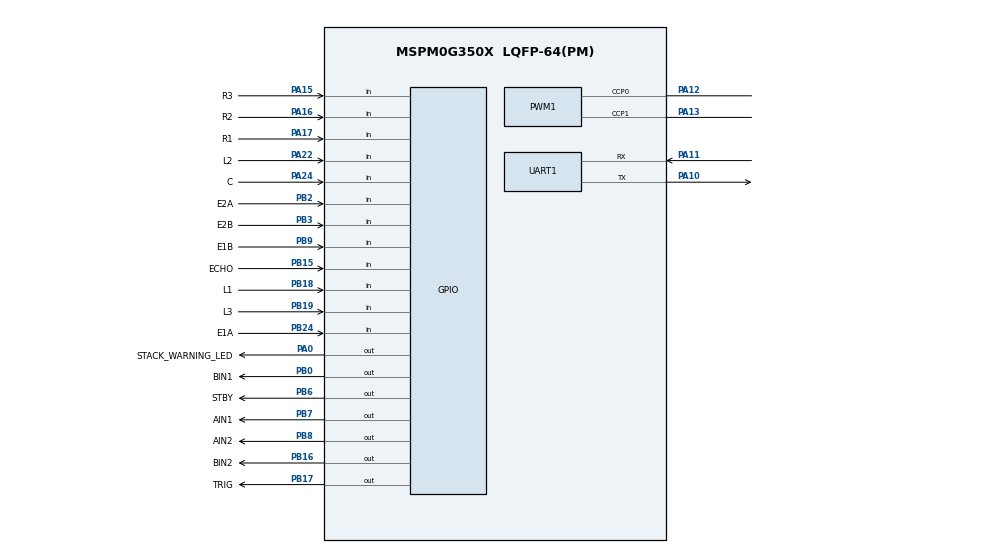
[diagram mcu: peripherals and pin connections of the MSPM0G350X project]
/**
 * @cliArgs --device "MSPM0G350X" --part "Default" --package "LQFP-64(PM)" --product "mspm0_sdk@2.10.00.04"
 * @versions {"tool":"1.27.0+4565"}
 */

/**
 * Import the modules used in this configuration.
 */
const Board         = scripting.addModule("/ti/driverlib/Board");
const GPIO          = scripting.addModule("/ti/driverlib/GPIO", {}, false);
const GPIO1         = GPIO.addInstance();
const GPIO2         = GPIO.addInstance();
const GPIO3         = GPIO.addInstance();
const GPIO4         = GPIO.addInstance();
const PWM           = scripting.addModule("/ti/driverlib/PWM", {}, false);
const PWM1          = PWM.addInstance();
const SYSCTL        = scripting.addModule("/ti/driverlib/SYSCTL");
const TIMER         = scripting.addModule("/ti/driverlib/TIMER", {}, false);
const TIMER1        = TIMER.addInstance();
const UART          = scripting.addModule("/ti/driverlib/UART", {}, false);
const UART1         = UART.addInstance();
const ProjectConfig = scripting.addModule("/ti/project_config/ProjectConfig");

/**
 * Write custom configuration values to the imported modules.
 */
const divider9       = system.clockTree["UDIV"];
divider9.divideValue = 2;

const multiplier2         = system.clockTree["PLL_QDIV"];
multiplier2.multiplyValue = 5;

const mux8       = system.clockTree["HSCLKMUX"];
mux8.inputSelect = "HSCLKMUX_SYSPLL0";

Board.configureUnused = true;
Board.unusedDirection = "INPUT";

GPIO1.$name                          = "GPIO_LEDS";
GPIO1.associatedPins[0].assignedPin  = "0";
GPIO1.associatedPins[0].$name        = "STACK_WARNING_LED";
GPIO1.associatedPins[0].assignedPort = "PORTA";
GPIO1.associatedPins[0].initialValue = "SET";
GPIO1.associatedPins[0].pin.$assign  = "PA0";

GPIO2.$name                          = "GPIO_TRACE";
GPIO2.associatedPins.create(7);
GPIO2.associatedPins[0].direction    = "INPUT";
GPIO2.associatedPins[0].assignedPort = "PORTB";
GPIO2.associatedPins[0].assignedPin  = "19";
GPIO2.associatedPins[0].$name        = "L3";
GPIO2.associatedPins[0].pin.$assign  = "PB19";
GPIO2.associatedPins[1].direction    = "INPUT";
GPIO2.associatedPins[1].assignedPin  = "22";
GPIO2.associatedPins[1].assignedPort = "PORTA";
GPIO2.associatedPins[1].$name        = "L2";
GPIO2.associatedPins[1].pin.$assign  = "PA22";
GPIO2.associatedPins[2].direction    = "INPUT";
GPIO2.associatedPins[2].assignedPort = "PORTB";
GPIO2.associatedPins[2].assignedPin  = "18";
GPIO2.associatedPins[2].$name        = "L1";
GPIO2.associatedPins[2].pin.$assign  = "PB18";
GPIO2.associatedPins[3].direction    = "INPUT";
GPIO2.associatedPins[3].assignedPort = "PORTA";
GPIO2.associatedPins[3].$name        = "C";
GPIO2.associatedPins[3].assignedPin  = "24";
GPIO2.associatedPins[3].pin.$assign  = "PA24";
GPIO2.associatedPins[4].direction    = "INPUT";
GPIO2.associatedPins[4].assignedPort = "PORTA";
GPIO2.associatedPins[4].$name        = "R1";
GPIO2.associatedPins[4].assignedPin  = "17";
GPIO2.associatedPins[4].pin.$assign  = "PA17";
GPIO2.associatedPins[5].direction    = "INPUT";
GPIO2.associatedPins[5].assignedPort = "PORTA";
GPIO2.associatedPins[5].$name        = "R2";
GPIO2.associatedPins[5].assignedPin  = "16";
GPIO2.associatedPins[5].pin.$assign  = "PA16";
GPIO2.associatedPins[6].direction    = "INPUT";
GPIO2.associatedPins[6].assignedPort = "PORTA";
GPIO2.associatedPins[6].$name        = "R3";
GPIO2.associatedPins[6].assignedPin  = "15";
GPIO2.associatedPins[6].pin.$assign  = "PA15";

GPIO3.$name                               = "GPIO_MOTOR";
GPIO3.port                                = "PORTB";
GPIO3.associatedPins.create(9);
GPIO3.associatedPins[0].$name             = "STBY";
GPIO3.associatedPins[0].assignedPin       = "6";
GPIO3.associatedPins[0].pin.$assign       = "PB6";
GPIO3.associatedPins[1].$name             = "AIN1";
GPIO3.associatedPins[1].assignedPin       = "7";
GPIO3.associatedPins[1].pin.$assign       = "PB7";
GPIO3.associatedPins[2].$name             = "AIN2";
GPIO3.associatedPins[2].assignedPin       = "8";
GPIO3.associatedPins[2].pin.$assign       = "PB8";
GPIO3.associatedPins[3].$name             = "BIN1";
GPIO3.associatedPins[3].assignedPin       = "0";
GPIO3.associatedPins[3].pin.$assign       = "PB0";
GPIO3.associatedPins[4].$name             = "BIN2";
GPIO3.associatedPins[4].assignedPin       = "16";
GPIO3.associatedPins[4].pin.$assign       = "PB16";
GPIO3.associatedPins[5].$name             = "E1A";
GPIO3.associatedPins[5].direction         = "INPUT";
GPIO3.associatedPins[5].interruptEn       = true;
GPIO3.associatedPins[5].interruptPriority = "2";
GPIO3.associatedPins[5].polarity          = "RISE_FALL";
GPIO3.associatedPins[5].assignedPin       = "24";
GPIO3.associatedPins[5].pin.$assign       = "PB24";
GPIO3.associatedPins[6].$name             = "E1B";
GPIO3.associatedPins[6].direction         = "INPUT";
GPIO3.associatedPins[6].interruptEn       = true;
GPIO3.associatedPins[6].interruptPriority = "2";
GPIO3.associatedPins[6].polarity          = "RISE_FALL";
GPIO3.associatedPins[6].assignedPin       = "9";
GPIO3.associatedPins[6].pin.$assign       = "PB9";
GPIO3.associatedPins[7].$name             = "E2A";
GPIO3.associatedPins[7].direction         = "INPUT";
GPIO3.associatedPins[7].polarity          = "RISE_FALL";
GPIO3.associatedPins[7].interruptEn       = true;
GPIO3.associatedPins[7].interruptPriority = "2";
GPIO3.associatedPins[7].assignedPin       = "2";
GPIO3.associatedPins[7].pin.$assign       = "PB2";
GPIO3.associatedPins[8].$name             = "E2B";
GPIO3.associatedPins[8].direction         = "INPUT";
GPIO3.associatedPins[8].interruptEn       = true;
GPIO3.associatedPins[8].interruptPriority = "2";
GPIO3.associatedPins[8].polarity          = "RISE_FALL";
GPIO3.associatedPins[8].assignedPin       = "3";
GPIO3.associatedPins[8].pin.$assign       = "PB3";

GPIO4.$name                               = "GPIO_HCSR04";
GPIO4.associatedPins.create(2);
GPIO4.associatedPins[0].assignedPort      = "PORTB";
GPIO4.associatedPins[0].assignedPin       = "17";
GPIO4.associatedPins[0].$name             = "TRIG";
GPIO4.associatedPins[0].pin.$assign       = "PB17";
GPIO4.associatedPins[1].direction         = "INPUT";
GPIO4.associatedPins[1].interruptEn       = true;
GPIO4.associatedPins[1].interruptPriority = "1";
GPIO4.associatedPins[1].polarity          = "RISE_FALL";
GPIO4.associatedPins[1].assignedPort      = "PORTB";
GPIO4.associatedPins[1].assignedPin       = "15";
GPIO4.associatedPins[1].$name             = "ECHO";
GPIO4.associatedPins[1].pin.$assign       = "PB15";

PWM1.dutyArgs                           = "[25,75,0,0]";
PWM1.timerCount                         = 1024;
PWM1.$name                              = "MOTOR_PWM";
PWM1.pwmMode                            = "EDGE_ALIGN_UP";
PWM1.clockPrescale                      = 4;
PWM1.peripheral.$assign                 = "TIMG0";
PWM1.peripheral.ccp0Pin.$assign         = "PA12";
PWM1.peripheral.ccp1Pin.$assign         = "PA13";
PWM1.PWM_CHANNEL_0.$name                = "ti_driverlib_pwm_PWMTimerCC0";
PWM1.PWM_CHANNEL_0.dutyCycle            = 10;
PWM1.PWM_CHANNEL_1.$name                = "ti_driverlib_pwm_PWMTimerCC1";
PWM1.PWM_CHANNEL_1.dutyCycle            = 10;
PWM1.ccp0PinConfig.direction            = scripting.forceWrite("OUTPUT");
PWM1.ccp0PinConfig.hideOutputInversion  = scripting.forceWrite(false);
PWM1.ccp0PinConfig.onlyInternalResistor = scripting.forceWrite(false);
PWM1.ccp0PinConfig.passedPeripheralType = scripting.forceWrite("Digital");
PWM1.ccp0PinConfig.$name                = "ti_driverlib_gpio_GPIOPinGeneric2";
PWM1.ccp1PinConfig.direction            = scripting.forceWrite("OUTPUT");
PWM1.ccp1PinConfig.hideOutputInversion  = scripting.forceWrite(false);
PWM1.ccp1PinConfig.onlyInternalResistor = scripting.forceWrite(false);
PWM1.ccp1PinConfig.passedPeripheralType = scripting.forceWrite("Digital");
PWM1.ccp1PinConfig.$name                = "ti_driverlib_gpio_GPIOPinGeneric3";

SYSCTL.clockTreeEn = true;

TIMER1.$name              = "FREE_TIMER";
TIMER1.timerMode          = "PERIODIC_UP";
TIMER1.timerStartTimer    = true;
TIMER1.timerClkDiv        = 8;
TIMER1.timerPeriod        = "65535 us";
TIMER1.timerClkPrescale   = 5;
TIMER1.peripheral.$assign = "TIMG8";

UART1.enabledInterrupts                = ["RX"];
UART1.targetBaudRate                   = 115200;
UART1.$name                            = "UART_DEBUG";
UART1.peripheral.$assign               = "UART0";
UART1.peripheral.rxPin.$assign         = "PA11";
UART1.peripheral.txPin.$assign         = "PA10";
UART1.txPinConfig.direction            = scripting.forceWrite("OUTPUT");
UART1.txPinConfig.hideOutputInversion  = scripting.forceWrite(false);
UART1.txPinConfig.onlyInternalResistor = scripting.forceWrite(false);
UART1.txPinConfig.passedPeripheralType = scripting.forceWrite("Digital");
UART1.txPinConfig.$name                = "ti_driverlib_gpio_GPIOPinGeneric0";
UART1.rxPinConfig.hideOutputInversion  = scripting.forceWrite(false);
UART1.rxPinConfig.onlyInternalResistor = scripting.forceWrite(false);
UART1.rxPinConfig.passedPeripheralType = scripting.forceWrite("Digital");
UART1.rxPinConfig.$name                = "ti_driverlib_gpio_GPIOPinGeneric1";

ProjectConfig.genDisable = true;
scripting.suppress("Project Configuration File generation is disabled for this project\\. SysConfig Project Migration is not currently supported for this project\\.", ProjectConfig);

/**
 * Pinmux solution for unlocked pins/peripherals. This ensures that minor changes to the automatic solver in a future
 * version of the tool will not impact the pinmux you originally saw.  These lines can be completely deleted in order to
 * re-solve from scratch.
 */
Board.peripheral.$suggestSolution          = "DEBUGSS";
Board.peripheral.swclkPin.$suggestSolution = "PA20";
Board.peripheral.swdioPin.$suggestSolution = "PA19";
